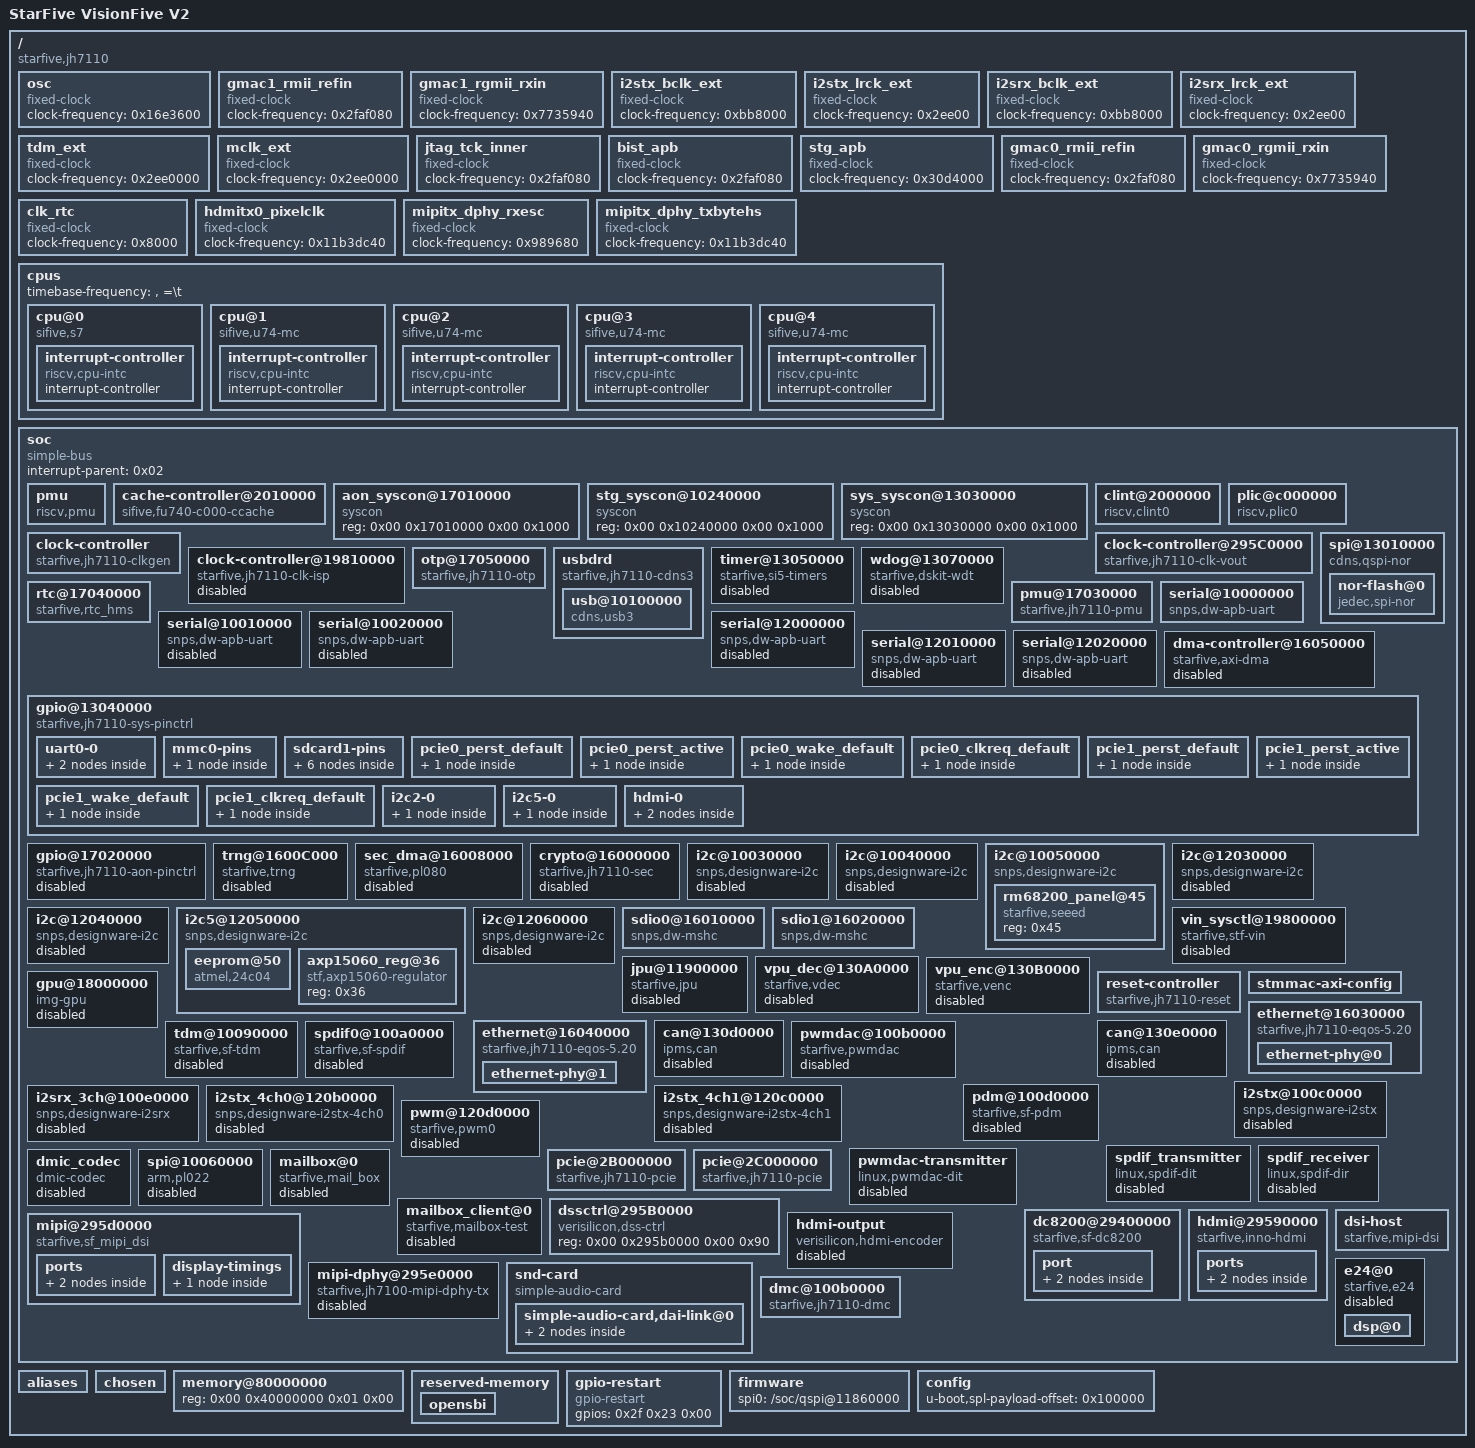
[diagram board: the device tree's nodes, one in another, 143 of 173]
/dts-v1/;

/ {
	serial-number = "VF7110B1-2253-D008E000-00005629";
	compatible = "starfive,jh7110";
	#address-cells = <0x02>;
	#size-cells = <0x02>;
	model = "StarFive VisionFive V2";

	osc {
		compatible = "fixed-clock";
		#clock-cells = <0x00>;
		clock-frequency = <0x16e3600>;
		u-boot,dm-spl;
		phandle = <0x08>;
	};

	gmac1_rmii_refin {
		compatible = "fixed-clock";
		#clock-cells = <0x00>;
		clock-frequency = <0x2faf080>;
		u-boot,dm-spl;
		phandle = <0x09>;
	};

	gmac1_rgmii_rxin {
		compatible = "fixed-clock";
		#clock-cells = <0x00>;
		clock-frequency = <0x7735940>;
		phandle = <0x30>;
	};

	i2stx_bclk_ext {
		compatible = "fixed-clock";
		#clock-cells = <0x00>;
		clock-frequency = <0xbb8000>;
		phandle = <0x31>;
	};

	i2stx_lrck_ext {
		compatible = "fixed-clock";
		#clock-cells = <0x00>;
		clock-frequency = <0x2ee00>;
		phandle = <0x32>;
	};

	i2srx_bclk_ext {
		compatible = "fixed-clock";
		#clock-cells = <0x00>;
		clock-frequency = <0xbb8000>;
		phandle = <0x33>;
	};

	i2srx_lrck_ext {
		compatible = "fixed-clock";
		#clock-cells = <0x00>;
		clock-frequency = <0x2ee00>;
		phandle = <0x34>;
	};

	tdm_ext {
		compatible = "fixed-clock";
		#clock-cells = <0x00>;
		clock-frequency = <0x2ee0000>;
		phandle = <0x35>;
	};

	mclk_ext {
		compatible = "fixed-clock";
		#clock-cells = <0x00>;
		clock-frequency = <0x2ee0000>;
		phandle = <0x36>;
	};

	jtag_tck_inner {
		compatible = "fixed-clock";
		#clock-cells = <0x00>;
		clock-frequency = <0x2faf080>;
		phandle = <0x37>;
	};

	bist_apb {
		compatible = "fixed-clock";
		#clock-cells = <0x00>;
		clock-frequency = <0x2faf080>;
		phandle = <0x38>;
	};

	stg_apb {
		compatible = "fixed-clock";
		#clock-cells = <0x00>;
		clock-frequency = <0x30d4000>;
		u-boot,dm-spl;
		phandle = <0x0a>;
	};

	gmac0_rmii_refin {
		compatible = "fixed-clock";
		#clock-cells = <0x00>;
		clock-frequency = <0x2faf080>;
		u-boot,dm-spl;
		phandle = <0x0b>;
	};

	gmac0_rgmii_rxin {
		compatible = "fixed-clock";
		#clock-cells = <0x00>;
		clock-frequency = <0x7735940>;
		phandle = <0x39>;
	};

	clk_rtc {
		compatible = "fixed-clock";
		#clock-cells = <0x00>;
		clock-frequency = <0x8000>;
		phandle = <0x3a>;
	};

	hdmitx0_pixelclk {
		compatible = "fixed-clock";
		#clock-cells = <0x00>;
		clock-frequency = <0x11b3dc40>;
		phandle = <0x0c>;
	};

	mipitx_dphy_rxesc {
		compatible = "fixed-clock";
		#clock-cells = <0x00>;
		clock-frequency = <0x989680>;
		phandle = <0x0d>;
	};

	mipitx_dphy_txbytehs {
		compatible = "fixed-clock";
		#clock-cells = <0x00>;
		clock-frequency = <0x11b3dc40>;
		phandle = <0x0e>;
	};

	cpus {
		#address-cells = <0x01>;
		#size-cells = <0x00>;
		u-boot,dm-spl;
		timebase-frequency = "", "=\t";
		phandle = <0x3b>;

		cpu@0 {
			compatible = "sifive,s7", "riscv";
			reg = <0x00>;
			d-cache-block-size = <0x40>;
			d-cache-sets = <0x40>;
			d-cache-size = <0x2000>;
			d-tlb-sets = <0x01>;
			d-tlb-size = <0x28>;
			device_type = "cpu";
			i-cache-block-size = <0x40>;
			i-cache-sets = <0x40>;
			i-cache-size = <0x4000>;
			i-tlb-sets = <0x01>;
			i-tlb-size = <0x28>;
			mmu-type = "riscv,sv39";
			next-level-cache = <0x01>;
			riscv,isa = "rv64imacu_zba_zbb";
			tlb-split;
			status = "okay";
			u-boot,dm-spl;
			phandle = <0x3c>;

			interrupt-controller {
				#interrupt-cells = <0x01>;
				compatible = "riscv,cpu-intc";
				interrupt-controller;
				u-boot,dm-spl;
				phandle = <0x03>;
			};
		};

		cpu@1 {
			compatible = "sifive,u74-mc", "riscv";
			reg = <0x01>;
			d-cache-block-size = <0x40>;
			d-cache-sets = <0x40>;
			d-cache-size = <0x8000>;
			d-tlb-sets = <0x01>;
			d-tlb-size = <0x28>;
			device_type = "cpu";
			i-cache-block-size = <0x40>;
			i-cache-sets = <0x40>;
			i-cache-size = <0x8000>;
			i-tlb-sets = <0x01>;
			i-tlb-size = <0x28>;
			mmu-type = "riscv,sv39";
			next-level-cache = <0x01>;
			riscv,isa = "rv64imafdcbsux_zba_zbb";
			tlb-split;
			status = "okay";
			u-boot,dm-spl;
			phandle = <0x3d>;

			interrupt-controller {
				#interrupt-cells = <0x01>;
				compatible = "riscv,cpu-intc";
				interrupt-controller;
				u-boot,dm-spl;
				phandle = <0x04>;
			};
		};

		cpu@2 {
			compatible = "sifive,u74-mc", "riscv";
			reg = <0x02>;
			d-cache-block-size = <0x40>;
			d-cache-sets = <0x40>;
			d-cache-size = <0x8000>;
			d-tlb-sets = <0x01>;
			d-tlb-size = <0x28>;
			device_type = "cpu";
			i-cache-block-size = <0x40>;
			i-cache-sets = <0x40>;
			i-cache-size = <0x8000>;
			i-tlb-sets = <0x01>;
			i-tlb-size = <0x28>;
			mmu-type = "riscv,sv39";
			next-level-cache = <0x01>;
			riscv,isa = "rv64imafdcbsux_zba_zbb";
			tlb-split;
			status = "okay";
			u-boot,dm-spl;
			phandle = <0x3e>;

			interrupt-controller {
				#interrupt-cells = <0x01>;
				compatible = "riscv,cpu-intc";
				interrupt-controller;
				u-boot,dm-spl;
				phandle = <0x05>;
			};
		};

		cpu@3 {
			compatible = "sifive,u74-mc", "riscv";
			reg = <0x03>;
			d-cache-block-size = <0x40>;
			d-cache-sets = <0x40>;
			d-cache-size = <0x8000>;
			d-tlb-sets = <0x01>;
			d-tlb-size = <0x28>;
			device_type = "cpu";
			i-cache-block-size = <0x40>;
			i-cache-sets = <0x40>;
			i-cache-size = <0x8000>;
			i-tlb-sets = <0x01>;
			i-tlb-size = <0x28>;
			mmu-type = "riscv,sv39";
			next-level-cache = <0x01>;
			riscv,isa = "rv64imafdcbsux_zba_zbb";
			tlb-split;
			status = "okay";
			u-boot,dm-spl;
			phandle = <0x3f>;

			interrupt-controller {
				#interrupt-cells = <0x01>;
				compatible = "riscv,cpu-intc";
				interrupt-controller;
				u-boot,dm-spl;
				phandle = <0x06>;
			};
		};

		cpu@4 {
			compatible = "sifive,u74-mc", "riscv";
			reg = <0x04>;
			d-cache-block-size = <0x40>;
			d-cache-sets = <0x40>;
			d-cache-size = <0x8000>;
			d-tlb-sets = <0x01>;
			d-tlb-size = <0x28>;
			device_type = "cpu";
			i-cache-block-size = <0x40>;
			i-cache-sets = <0x40>;
			i-cache-size = <0x8000>;
			i-tlb-sets = <0x01>;
			i-tlb-size = <0x28>;
			mmu-type = "riscv,sv39";
			next-level-cache = <0x01>;
			riscv,isa = "rv64imafdcbsux_zba_zbb";
			tlb-split;
			status = "okay";
			u-boot,dm-spl;
			phandle = <0x40>;

			interrupt-controller {
				#interrupt-cells = <0x01>;
				compatible = "riscv,cpu-intc";
				interrupt-controller;
				u-boot,dm-spl;
				phandle = <0x07>;
			};
		};
	};

	soc {
		compatible = "simple-bus";
		interrupt-parent = <0x02>;
		#address-cells = <0x02>;
		#size-cells = <0x02>;
		#clock-cells = <0x01>;
		ranges;
		u-boot,dm-spl;
		phandle = <0x41>;

		pmu {
			compatible = "riscv,pmu";
			riscv,event-to-mhpmcounters = <0x05 0x06 0x18>;
			riscv,event-to-mhpmevent = <0x05 0x00 0x4000 0x06 0x00 0x4001>;
			riscv,raw-event-to-mhpmcounters = <0x00 0x100 0xffffffff 0xffffffff 0x18 0x00 0x200 0xffffffff 0xffffffff 0x18 0x00 0x400 0xffffffff 0xffffffff 0x18 0x00 0x800 0xffffffff 0xffffffff 0x18 0x00 0x1000 0xffffffff 0xffffffff 0x18 0x00 0x2000 0xffffffff 0xffffffff 0x18 0x00 0x4000 0xffffffff 0xffffffff 0x18 0x00 0x8000 0xffffffff 0xffffffff 0x18 0x00 0x10000 0xffffffff 0xffffffff 0x18 0x00 0x20000 0xffffffff 0xffffffff 0x18 0x00 0x40000 0xffffffff 0xffffffff 0x18 0x00 0x80000 0xffffffff 0xffffffff 0x18 0x00 0x100000 0xffffffff 0xffffffff 0x18 0x00 0x200000 0xffffffff 0xffffffff 0x18 0x00 0x400000 0xffffffff 0xffffffff 0x18 0x00 0x800000 0xffffffff 0xffffffff 0x18 0x00 0x1000000 0xffffffff 0xffffffff 0x18 0x00 0x2000000 0xffffffff 0xffffffff 0x18 0x00 0x101 0xffffffff 0xffffffff 0x18 0x00 0x201 0xffffffff 0xffffffff 0x18 0x00 0x401 0xffffffff 0xffffffff 0x18 0x00 0x801 0xffffffff 0xffffffff 0x18 0x00 0x1001 0xffffffff 0xffffffff 0x18 0x00 0x2001 0xffffffff 0xffffffff 0x18 0x00 0x4001 0xffffffff 0xffffffff 0x18 0x00 0x8001 0xffffffff 0xffffffff 0x18 0x00 0x10001 0xffffffff 0xffffffff 0x18 0x00 0x20001 0xffffffff 0xffffffff 0x18 0x00 0x40001 0xffffffff 0xffffffff 0x18 0x00 0x102 0xffffffff 0xffffffff 0x18 0x00 0x202 0xffffffff 0xffffffff 0x18 0x00 0x402 0xffffffff 0xffffffff 0x18 0x00 0x802 0xffffffff 0xffffffff 0x18 0x00 0x1002 0xffffffff 0xffffffff 0x18 0x00 0x2002 0xffffffff 0xffffffff 0x18>;
		};

		cache-controller@2010000 {
			compatible = "sifive,fu740-c000-ccache", "cache";
			reg = <0x00 0x2010000 0x00 0x4000 0x00 0x2030000 0x00 0x80000 0x00 0x8000000 0x00 0x2000000>;
			reg-names = "control", "prefetcher", "sideband";
			interrupts = <0x01 0x03 0x04 0x02>;
			cache-block-size = <0x40>;
			cache-level = <0x02>;
			cache-sets = <0x800>;
			cache-size = <0x200000>;
			cache-unified;
			prefetch-dist-size = <0x04>;
			prefetch-hart-mask = <0x1e>;
			prefetch-enable;
			phandle = <0x01>;
		};

		aon_syscon@17010000 {
			compatible = "syscon";
			reg = <0x00 0x17010000 0x00 0x1000>;
			phandle = <0x42>;
		};

		stg_syscon@10240000 {
			compatible = "syscon";
			reg = <0x00 0x10240000 0x00 0x1000>;
			phandle = <0x11>;
		};

		sys_syscon@13030000 {
			compatible = "syscon";
			reg = <0x00 0x13030000 0x00 0x1000>;
			phandle = <0x12>;
		};

		clint@2000000 {
			compatible = "riscv,clint0";
			reg = <0x00 0x2000000 0x00 0x10000>;
			reg-names = "control";
			interrupts-extended = <0x03 0x03 0x03 0x07 0x04 0x03 0x04 0x07 0x05 0x03 0x05 0x07 0x06 0x03 0x06 0x07 0x07 0x03 0x07 0x07>;
			#interrupt-cells = <0x01>;
			u-boot,dm-spl;
			phandle = <0x43>;
		};

		plic@c000000 {
			compatible = "riscv,plic0";
			reg = <0x00 0xc000000 0x00 0x4000000>;
			reg-names = "control";
			interrupts-extended = <0x03 0x0b 0x04 0x0b 0x04 0x09 0x05 0x0b 0x05 0x09 0x06 0x0b 0x06 0x09 0x07 0x0b 0x07 0x09>;
			interrupt-controller;
			#interrupt-cells = <0x01>;
			riscv,max-priority = <0x07>;
			riscv,ndev = <0x88>;
			phandle = <0x02>;
		};

		clock-controller {
			compatible = "starfive,jh7110-clkgen";
			reg = <0x00 0x13020000 0x00 0x10000 0x00 0x10230000 0x00 0x10000 0x00 0x17000000 0x00 0x10000>;
			reg-names = "sys", "stg", "aon";
			clocks = <0x08 0x09 0x0a 0x0b>;
			clock-names = "osc", "gmac1_rmii_refin", "stg_apb", "gmac0_rmii_refin";
			#clock-cells = <0x01>;
			status = "okay";
			u-boot,dm-spl;
			phandle = <0x0f>;
		};

		clock-controller@295C0000 {
			compatible = "starfive,jh7110-clk-vout";
			reg = <0x00 0x295c0000 0x00 0x10000>;
			reg-names = "vout";
			clocks = <0x0c 0x0d 0x0e>;
			clock-names = "hdmitx0_pixelclk", "mipitx_dphy_rxesc", "mipitx_dphy_txbytehs";
			#clock-cells = <0x01>;
			status = "okay";
			phandle = <0x24>;
		};

		clock-controller@19810000 {
			compatible = "starfive,jh7110-clk-isp";
			reg = <0x00 0x19810000 0x00 0x10000>;
			reg-names = "isp";
			#clock-cells = <0x01>;
			clocks = <0x0f 0x10a 0x0f 0x33 0x0f 0x34>;
			clock-names = "u0_dom_isp_top_clk_dom_isp_top_clk_dvp", "u0_dom_isp_top_clk_dom_isp_top_clk_ispcore_2x", "u0_dom_isp_top_clk_dom_isp_top_clk_isp_axi";
			resets = <0x10 0x29 0x10 0x2a>;
			reset-names = "rst_isp_top_n", "rst_isp_top_axi";
			status = "disabled";
			phandle = <0x18>;
		};

		spi@13010000 {
			compatible = "cdns,qspi-nor";
			#address-cells = <0x01>;
			#size-cells = <0x00>;
			reg = <0x00 0x13010000 0x00 0x10000 0x00 0x21000000 0x00 0x400000>;
			clocks = <0x0f 0x5a>;
			clock-names = "clk_ref";
			resets = <0x10 0x3e 0x10 0x3d 0x10 0x3f>;
			resets-names = "rst_apb", "rst_ahb", "rst_ref";
			cdns,fifo-depth = <0x100>;
			cdns,fifo-width = <0x04>;
			spi-max-frequency = <0xee6b280>;
			status = "okay";
			u-boot,dm-spl;
			phandle = <0x44>;

			nor-flash@0 {
				compatible = "jedec,spi-nor";
				reg = <0x00>;
				spi-max-frequency = <0x5f5e100>;
				cdns,tshsl-ns = <0x01>;
				cdns,tsd2d-ns = <0x01>;
				cdns,tchsh-ns = <0x01>;
				cdns,tslch-ns = <0x01>;
				u-boot,dm-spl;
				phandle = <0x45>;
			};
		};

		otp@17050000 {
			compatible = "starfive,jh7110-otp";
			reg = <0x00 0x17050000 0x00 0x10000>;
			clock-frequency = "", "=\t";
			clocks = <0x0f 0xe4>;
			clock-names = "apb";
			phandle = <0x46>;
		};

		usbdrd {
			compatible = "starfive,jh7110-cdns3";
			dma-coherent;
			#address-cells = <0x02>;
			#size-cells = <0x02>;
			reg = <0x00 0x10210000 0x00 0x1000 0x00 0x10200000 0x00 0x1000>;
			clocks = <0x0f 0x5f 0x0f 0xc4 0x0f 0xc2 0x0f 0xc3 0x0f 0xbf 0x0f 0xc1 0x0f 0xc0>;
			clock-names = "125m", "app", "lpm", "stb", "apb", "axi", "utmi";
			resets = <0x10 0x8a 0x10 0x88 0x10 0x87 0x10 0x89>;
			reset-names = "pwrup", "apb", "axi", "utmi";
			starfive,stg-syscon = <0x11 0x04 0xc4 0x148 0x1f4>;
			starfive,sys-syscon = <0x12 0x18>;
			status = "okay";
			starfive,usb2-only = <0x01>;
			phandle = <0x47>;

			usb@10100000 {
				compatible = "cdns,usb3";
				reg = <0x00 0x10100000 0x00 0x10000 0x00 0x10110000 0x00 0x10000 0x00 0x10120000 0x00 0x10000>;
				reg-names = "otg", "xhci", "dev";
				interrupts = <0x64 0x6c 0x6e>;
				interrupt-names = "host", "peripheral", "otg";
				phy-names = "cdns3,usb3-phy", "cnds3,usb2-phy";
				maximum-speed = "super-speed";
				dr_mode = "peripheral";
				phandle = <0x48>;
			};
		};

		timer@13050000 {
			compatible = "starfive,si5-timers";
			reg = <0x00 0x13050000 0x00 0x10000>;
			interrupts = <0x45 0x46 0x47 0x48>;
			interrupt-names = "timer0", "timer1", "timer2", "timer3";
			clocks = <0x0f 0x7d 0x0f 0x7e 0x0f 0x7f 0x0f 0x80 0x0f 0x7c>;
			clock-names = "timer0", "timer1", "timer2", "timer3", "apb_clk";
			clock-frequency = <0x1e8480>;
			status = "disabled";
			phandle = <0x49>;
		};

		wdog@13070000 {
			compatible = "starfive,dskit-wdt";
			reg = <0x00 0x13070000 0x00 0x10000>;
			interrupts = <0x44>;
			interrupt-names = "wdog";
			clock-frequency = <0x1e8480>;
			clocks = <0x0f 0x7b 0x0f 0x7a>;
			clock-names = "core_clk", "apb_clk";
			resets = <0x10 0x6d 0x10 0x6e>;
			reset-names = "rst_apb", "rst_core";
			timeout-sec = <0x0f>;
			status = "disabled";
			phandle = <0x4a>;
		};

		rtc@17040000 {
			compatible = "starfive,rtc_hms";
			reg = <0x00 0x17040000 0x00 0x10000>;
			interrupts = <0x0a 0x0b 0x0c>;
			interrupt-names = "rtc_ms_pulse", "rtc_sec_pulse", "rtc";
			clocks = <0x0f 0xe5 0x0f 0xe8>;
			clock-names = "pclk", "cal_clk";
			resets = <0x10 0xa5 0x10 0xa6 0x10 0xa7>;
			reset-names = "rst_apb", "rst_cal", "rst_osc";
			rtc,cal-clock-freq = <0xf4240>;
			status = "okay";
			phandle = <0x4b>;
		};

		pmu@17030000 {
			compatible = "starfive,jh7110-pmu";
			reg = <0x00 0x17030000 0x00 0x10000>;
			interrupts = <0x6f>;
			status = "okay";
			phandle = <0x4c>;
		};

		serial@10000000 {
			compatible = "snps,dw-apb-uart";
			reg = <0x00 0x10000000 0x00 0x10000>;
			reg-io-width = <0x04>;
			reg-shift = <0x02>;
			clocks = <0x0f 0x92 0x0f 0x91>;
			clock-names = "baudclk", "apb_pclk";
			resets = <0x10 0x53 0x10 0x54>;
			interrupts = <0x20>;
			status = "okay";
			reg-offset = <0x00>;
			current-speed = <0x1c200>;
			pinctrl-names = "default";
			pinctrl-0 = <0x13>;
			clock-frequency = <0x16e3600>;
			u-boot,dm-spl;
			phandle = <0x4d>;
		};

		serial@10010000 {
			compatible = "snps,dw-apb-uart";
			reg = <0x00 0x10010000 0x00 0x10000>;
			reg-io-width = <0x04>;
			reg-shift = <0x02>;
			clocks = <0x0f 0x94 0x0f 0x93>;
			clock-names = "baudclk", "apb_pclk";
			resets = <0x10 0x55 0x10 0x56>;
			interrupts = <0x21>;
			status = "disabled";
			phandle = <0x4e>;
		};

		serial@10020000 {
			compatible = "snps,dw-apb-uart";
			reg = <0x00 0x10020000 0x00 0x10000>;
			reg-io-width = <0x04>;
			reg-shift = <0x02>;
			clocks = <0x0f 0x96 0x0f 0x95>;
			clock-names = "baudclk", "apb_pclk";
			resets = <0x10 0x57 0x10 0x58>;
			interrupts = <0x22>;
			status = "disabled";
			phandle = <0x4f>;
		};

		serial@12000000 {
			compatible = "snps,dw-apb-uart";
			reg = <0x00 0x12000000 0x00 0x10000>;
			reg-io-width = <0x04>;
			reg-shift = <0x02>;
			clocks = <0x0f 0x98 0x0f 0x97>;
			clock-names = "baudclk", "apb_pclk";
			resets = <0x10 0x59 0x10 0x5a>;
			interrupts = <0x2d>;
			status = "disabled";
			phandle = <0x50>;
		};

		serial@12010000 {
			compatible = "snps,dw-apb-uart";
			reg = <0x00 0x12010000 0x00 0x10000>;
			reg-io-width = <0x04>;
			reg-shift = <0x02>;
			clocks = <0x0f 0x9a 0x0f 0x99>;
			clock-names = "baudclk", "apb_pclk";
			resets = <0x10 0x5b 0x10 0x5c>;
			interrupts = <0x2e>;
			status = "disabled";
			phandle = <0x51>;
		};

		serial@12020000 {
			compatible = "snps,dw-apb-uart";
			reg = <0x00 0x12020000 0x00 0x10000>;
			reg-io-width = <0x04>;
			reg-shift = <0x02>;
			clocks = <0x0f 0x9c 0x0f 0x9b>;
			clock-names = "baudclk", "apb_pclk";
			resets = <0x10 0x5d 0x10 0x5e>;
			interrupts = <0x2f>;
			status = "disabled";
			phandle = <0x52>;
		};

		dma-controller@16050000 {
			compatible = "starfive,axi-dma";
			reg = <0x00 0x16050000 0x00 0x10000>;
			clocks = <0x0f 0xd9 0x0f 0xda>;
			clock-names = "core-clk", "cfgr-clk";
			resets = <0x10 0x85 0x10 0x86>;
			reset-names = "rst_axi", "rst_ahb";
			interrupts = <0x49>;
			#dma-cells = <0x02>;
			dma-channels = <0x04>;
			snps,dma-masters = <0x01>;
			snps,data-width = <0x03>;
			snps,num-hs-if = <0x38>;
			snps,block-size = <0x10000 0x10000 0x10000 0x10000>;
			snps,priority = <0x00 0x01 0x02 0x03>;
			snps,axi-max-burst-len = <0x10>;
			status = "disabled";
			phandle = <0x1a>;
		};

		gpio@13040000 {
			compatible = "starfive,jh7110-sys-pinctrl";
			reg = <0x00 0x13040000 0x00 0x10000>;
			reg-names = "control";
			interrupts = <0x5b>;
			interrupt-controller;
			gpio-controller;
			#gpio-cells = <0x02>;
			ngpios = <0x40>;
			status = "okay";
			u-boot,dm-spl;
			phandle = <0x2f>;

			uart0-0 {
				phandle = <0x13>;

				tx-pins {
					pinmux = <0xff140005>;
					bias-disable;
					drive-strength = <0x0c>;
					input-disable;
					input-schmitt-disable;
					slew-rate = <0x00>;
				};

				rx-pins {
					pinmux = <0xe000406>;
					bias-pull-up;
					drive-strength = <0x02>;
					input-enable;
					input-schmitt-enable;
					slew-rate = <0x00>;
				};
			};

			mmc0-pins {
				phandle = <0x16>;

				mmc0-pins-rest {
					pinmux = <0xff13003e>;
					bias-pull-up;
					drive-strength = <0x0c>;
					input-disable;
					input-schmitt-disable;
					slew-rate = <0x00>;
				};
			};

			sdcard1-pins {
				phandle = <0x17>;

				sdcard1-pins0 {
					pinmux = <0xff37000a>;
					bias-pull-up;
					drive-strength = <0x0c>;
					input-disable;
					input-schmitt-disable;
					slew-rate = <0x00>;
				};

				sdcard1-pins1 {
					pinmux = <0x2c394c09>;
					bias-pull-up;
					drive-strength = <0x0c>;
					input-enable;
					input-schmitt-enable;
					slew-rate = <0x00>;
				};

				sdcard1-pins2 {
					pinmux = <0x2d3a500b>;
					bias-pull-up;
					drive-strength = <0x0c>;
					input-enable;
					input-schmitt-enable;
					slew-rate = <0x00>;
				};

				sdcard1-pins3 {
					pinmux = <0x2e3b540c>;
					bias-pull-up;
					drive-strength = <0x0c>;
					input-enable;
					input-schmitt-enable;
					slew-rate = <0x00>;
				};

				sdcard1-pins4 {
					pinmux = <0x2f3c5807>;
					bias-pull-up;
					drive-strength = <0x0c>;
					input-enable;
					input-schmitt-enable;
					slew-rate = <0x00>;
				};

				sdcard1-pins5 {
					pinmux = <0x303d5c08>;
					bias-pull-up;
					drive-strength = <0x0c>;
					input-enable;
					input-schmitt-enable;
					slew-rate = <0x00>;
				};
			};

			pcie0_perst_default {
				phandle = <0x1b>;

				perst-pins {
					pinmux = <0xff01001a>;
					drive-strength = <0x02>;
					input-disable;
					input-schmitt-disable;
					slew-rate = <0x00>;
				};
			};

			pcie0_perst_active {
				phandle = <0x1c>;

				perst-pins {
					pinmux = <0xff00001a>;
					drive-strength = <0x02>;
					input-disable;
					input-schmitt-disable;
					slew-rate = <0x00>;
				};
			};

			pcie0_wake_default {
				phandle = <0x1d>;

				wake-pins {
					pinmux = <0xff010020>;
					drive-strength = <0x02>;
					input-enable;
					input-schmitt-disable;
					slew-rate = <0x00>;
				};
			};

			pcie0_clkreq_default {
				phandle = <0x1e>;

				clkreq-pins {
					pinmux = <0xff01001b>;
					drive-strength = <0x02>;
					input-enable;
					input-schmitt-disable;
					slew-rate = <0x00>;
				};
			};

			pcie1_perst_default {
				phandle = <0x1f>;

				perst-pins {
					pinmux = <0xff01001c>;
					drive-strength = <0x02>;
					input-disable;
					input-schmitt-disable;
					slew-rate = <0x00>;
				};
			};

			pcie1_perst_active {
				phandle = <0x20>;

				perst-pins {
					pinmux = <0xff00001c>;
					drive-strength = <0x02>;
					input-disable;
					input-schmitt-disable;
					slew-rate = <0x00>;
				};
			};

			pcie1_wake_default {
				phandle = <0x21>;

				wake-pins {
					pinmux = <0xff010015>;
					drive-strength = <0x02>;
					input-enable;
					input-schmitt-disable;
					slew-rate = <0x00>;
				};
			};

			pcie1_clkreq_default {
				phandle = <0x22>;

				clkreq-pins {
					pinmux = <0xff01001d>;
					drive-strength = <0x02>;
					input-enable;
					input-schmitt-disable;
					slew-rate = <0x00>;
				};
			};

			i2c2-0 {
				phandle = <0x15>;

				i2c-pins {
					pinmux = <0x3b007803 0x3c007c02>;
					bias-disable;
					input-enable;
					input-schmitt-enable;
				};
			};

			i2c5-0 {
				phandle = <0x53>;

				i2c-pins {
					pinmux = <0x4f00a813 0x5000ac14>;
					bias-disable;
					input-enable;
					input-schmitt-enable;
				};
			};

			hdmi-0 {
				phandle = <0x27>;

				cec-pins {
					pinmux = <0x50a080e>;
					bias-pull-up;
					input-enable;
				};

				hpd-pins {
					pinmux = <0x800040f>;
					input-enable;
				};
			};
		};

		gpio@17020000 {
			compatible = "starfive,jh7110-aon-pinctrl";
			reg = <0x00 0x17020000 0x00 0x10000>;
			reg-names = "control";
			interrupts = <0x5a>;
			interrupt-controller;
			gpio-controller;
			#gpio-cells = <0x02>;
			ngpios = <0x04>;
			status = "disabled";
			u-boot,dm-spl;
			phandle = <0x54>;
		};

		trng@1600C000 {
			compatible = "starfive,trng";
			reg = <0x00 0x1600c000 0x00 0x4000>;
			clocks = <0x0f 0xcd 0x0f 0xce>;
			clock-names = "hclk", "miscahb_clk";
			resets = <0x10 0x83>;
			interrupts = <0x1e>;
			status = "disabled";
			phandle = <0x55>;
		};

		sec_dma@16008000 {
			compatible = "starfive,pl080";
			reg = <0x00 0x16008000 0x00 0x4000>;
			reg-names = "sec_dma";
			interrupts = <0x1d>;
			clocks = <0x0f 0xcd 0x0f 0xce>;
			clock-names = "sec_hclk", "sec_ahb";
			resets = <0x10 0x83>;
			reset-names = "sec_hre";
			lli-bus-interface-ahb1;
			mem-bus-interface-ahb1;
			memcpy-burst-size = <0x100>;
			memcpy-bus-width = <0x20>;
			#dma-cells = <0x02>;
			status = "disabled";
			phandle = <0x14>;
		};

		crypto@16000000 {
			compatible = "starfive,jh7110-sec";
			reg = <0x00 0x16000000 0x00 0x4000 0x00 0x16008000 0x00 0x4000>;
			reg-names = "secreg", "secdma";
			interrupts = <0x1c 0x1d>;
			interrupt-names = "secirq", "dmairq";
			clocks = <0x0f 0xcd 0x0f 0xce>;
			clock-names = "sec_hclk", "sec_ahb";
			resets = <0x10 0x83>;
			reset-names = "sec_hre";
			enable-dma = "true";
			dmas = <0x14 0x01 0x02 0x14 0x00 0x02>;
			dma-names = "sec_m", "sec_p";
			status = "disabled";
			phandle = <0x56>;
		};

		i2c@10030000 {
			compatible = "snps,designware-i2c";
			reg = <0x00 0x10030000 0x00 0x10000>;
			clocks = <0x0f 0x8a>;
			clock-names = "pclk";
			resets = <0x10 0x4c>;
			interrupts = <0x23>;
			#address-cells = <0x01>;
			#size-cells = <0x00>;
			status = "disabled";
			phandle = <0x57>;
		};

		i2c@10040000 {
			compatible = "snps,designware-i2c";
			reg = <0x00 0x10040000 0x00 0x10000>;
			clocks = <0x0f 0x8b>;
			clock-names = "pclk";
			resets = <0x10 0x4d>;
			interrupts = <0x24>;
			#address-cells = <0x01>;
			#size-cells = <0x00>;
			status = "disabled";
			phandle = <0x58>;
		};

		i2c@10050000 {
			compatible = "snps,designware-i2c";
			reg = <0x00 0x10050000 0x00 0x10000>;
			clocks = <0x0f 0x8c>;
			clock-names = "pclk";
			resets = <0x10 0x4e>;
			interrupts = <0x25>;
			#address-cells = <0x01>;
			#size-cells = <0x00>;
			status = "okay";
			clock-frequency = <0x186a0>;
			i2c-sda-hold-time-ns = <0x12c>;
			i2c-sda-falling-time-ns = <0xbb8>;
			i2c-scl-falling-time-ns = <0xbb8>;
			auto_calc_scl_lhcnt;
			pinctrl-names = "default";
			pinctrl-0 = <0x15>;
			phandle = <0x59>;

			rm68200_panel@45 {
				compatible = "starfive,seeed";
				reg = <0x45>;
				phandle = <0x29>;
			};
		};

		i2c@12030000 {
			compatible = "snps,designware-i2c";
			reg = <0x00 0x12030000 0x00 0x10000>;
			clocks = <0x0f 0x8d>;
			clock-names = "pclk";
			resets = <0x10 0x4f>;
			interrupts = <0x30>;
			#address-cells = <0x01>;
			#size-cells = <0x00>;
			status = "disabled";
			phandle = <0x5a>;
		};

		i2c@12040000 {
			compatible = "snps,designware-i2c";
			reg = <0x00 0x12040000 0x00 0x10000>;
			clocks = <0x0f 0x8e>;
			clock-names = "pclk";
			resets = <0x10 0x50>;
			interrupts = <0x31>;
			#address-cells = <0x01>;
			#size-cells = <0x00>;
			status = "disabled";
			phandle = <0x5b>;
		};

		i2c5@12050000 {
			compatible = "snps,designware-i2c";
			reg = <0x00 0x12050000 0x00 0x10000>;
			clocks = <0x0f 0x8f>;
			clock-names = "pclk";
			resets = <0x10 0x51>;
			interrupts = <0x32>;
			#address-cells = <0x01>;
			#size-cells = <0x00>;
			status = "okay";
			clock-frequency = <0x186a0>;
			i2c-sda-hold-time-ns = <0x12c>;
			i2c-sda-falling-time-ns = <0xbb8>;
			i2c-scl-falling-time-ns = <0xbb8>;
			auto_calc_scl_lhcnt;
			u-boot,dm-spl;
			phandle = <0x5c>;

			eeprom@50 {
				compatible = "atmel,24c04";
				reg = <0x50>;
				pagesize = <0x10>;
				u-boot,dm-spl;
			};

			axp15060_reg@36 {
				compatible = "stf,axp15060-regulator";
				reg = <0x36>;
				phandle = <0x5d>;
			};
		};

		i2c@12060000 {
			compatible = "snps,designware-i2c";
			reg = <0x00 0x12060000 0x00 0x10000>;
			clocks = <0x0f 0x90>;
			clock-names = "pclk";
			resets = <0x10 0x52>;
			interrupts = <0x33>;
			#address-cells = <0x01>;
			#size-cells = <0x00>;
			status = "disabled";
			phandle = <0x5e>;
		};

		sdio0@16010000 {
			compatible = "snps,dw-mshc";
			reg = <0x00 0x16010000 0x00 0x10000>;
			clocks = <0x0f 0x5b 0x0f 0x5d>;
			clock-names = "biu", "ciu";
			resets = <0x10 0x40>;
			reset-names = "reset";
			assigned-clocks = <0x0f 0x5d>;
			assigned-clock-rates = <0x2faf080>;
			fifo-depth = <0x20>;
			bus-width = <0x08>;
			pinctrl-names = "default";
			pinctrl-0 = <0x16>;
			status = "okay";
			u-boot,dm-spl;
			phandle = <0x5f>;
		};

		sdio1@16020000 {
			compatible = "snps,dw-mshc";
			reg = <0x00 0x16020000 0x00 0x10000>;
			clocks = <0x0f 0x5c 0x0f 0x5e>;
			clock-names = "biu", "ciu";
			resets = <0x10 0x41>;
			reset-names = "reset";
			assigned-clocks = <0x0f 0x5e>;
			assigned-clock-rates = <0x2faf080>;
			fifo-depth = <0x20>;
			bus-width = <0x04>;
			pinctrl-names = "default";
			pinctrl-0 = <0x17>;
			status = "okay";
			u-boot,dm-spl;
			phandle = <0x60>;
		};

		vin_sysctl@19800000 {
			compatible = "starfive,stf-vin";
			reg = <0x00 0x19800000 0x00 0x10000 0x00 0x19810000 0x00 0x10000 0x00 0x19820000 0x00 0x10000 0x00 0x19830000 0x00 0x10000 0x00 0x19840000 0x00 0x10000 0x00 0x19870000 0x00 0x30000 0x00 0x198a0000 0x00 0x30000 0x00 0x11840000 0x00 0x10000 0x00 0x17030000 0x00 0x10000 0x00 0x13020000 0x00 0x10000>;
			reg-names = "mipi0", "vclk", "vrst", "mipi1", "sctrl", "isp0", "isp1", "trst", "pmu", "syscrg";
			clocks = <0x18 0x00 0x18 0x06 0x18 0x07 0x18 0x0d 0x18 0x02 0x18 0x0c 0x18 0x01 0x18 0x08 0x18 0x09 0x18 0x0a 0x18 0x0b>;
			clock-names = "clk_apb_func", "clk_pclk", "clk_sys_clk", "clk_wrapper_clk_c", "clk_dvp_inv", "clk_axiwr", "clk_mipi_rx0_pxl", "clk_pixel_clk_if0", "clk_pixel_clk_if1", "clk_pixel_clk_if2", "clk_pixel_clk_if3";
			resets = <0x10 0xc0 0x10 0xc1 0x10 0xc4 0x10 0xc9 0x10 0xca 0x10 0xcb 0x10 0xc5 0x10 0xc6 0x10 0xc7 0x10 0xc8 0x10 0xc2 0x10 0xc3>;
			reset-names = "rst_wrapper_p", "rst_wrapper_c", "rst_pclk", "rst_sys_clk", "rst_axird", "rst_axiwr", "rst_pixel_clk_if0", "rst_pixel_clk_if1", "rst_pixel_clk_if2", "rst_pixel_clk_if3", "rst_m31dphy_hw", "rst_m31dphy_b09_always_on";
			interrupts = <0x5c 0x57 0x56>;
			status = "disabled";
			phandle = <0x61>;
		};

		jpu@11900000 {
			compatible = "starfive,jpu";
			reg = <0x00 0x13090000 0x00 0x300>;
			interrupts = <0x0e>;
			clocks = <0x0f 0x42 0x0f 0x43 0x0f 0x44>;
			clock-names = "axi_clk", "core_clk", "apb_clk";
			resets = <0x10 0x2c 0x10 0x2d 0x10 0x2e>;
			reset-names = "rst_axi", "rst_core", "rst_apb";
			status = "disabled";
			phandle = <0x62>;
		};

		vpu_dec@130A0000 {
			compatible = "starfive,vdec";
			reg = <0x00 0x130a0000 0x00 0x10000>;
			interrupts = <0x0d>;
			clocks = <0x0f 0x46 0x0f 0x47 0x0f 0x48 0x0f 0x49 0x0f 0x4c>;
			clock-names = "axi_clk", "bpu_clk", "vce_clk", "apb_clk", "noc_bus";
			resets = <0x10 0x2f 0x10 0x30 0x10 0x31 0x10 0x32 0x10 0x35>;
			reset-names = "rst_axi", "rst_bpu", "rst_vce", "rst_apb", "rst_sram";
			starfive,vdec_noc_ctrl;
			status = "disabled";
			phandle = <0x63>;
		};

		vpu_enc@130B0000 {
			compatible = "starfive,venc";
			reg = <0x00 0x130b0000 0x00 0x10000>;
			interrupts = <0x0f>;
			clocks = <0x0f 0x4e 0x0f 0x4f 0x0f 0x50 0x0f 0x51 0x0f 0x52>;
			clock-names = "axi_clk", "bpu_clk", "vce_clk", "apb_clk", "noc_bus";
			resets = <0x10 0x36 0x10 0x37 0x10 0x38 0x10 0x39 0x10 0x3a>;
			reset-names = "rst_axi", "rst_bpu", "rst_vce", "rst_apb", "rst_sram";
			starfive,venc_noc_ctrl;
			status = "disabled";
			phandle = <0x64>;
		};

		reset-controller {
			compatible = "starfive,jh7110-reset";
			reg = <0x00 0x13020000 0x00 0x10000 0x00 0x10230000 0x00 0x10000 0x00 0x17000000 0x00 0x10000 0x00 0x19810000 0x00 0x10000 0x00 0x295c0000 0x00 0x10000>;
			reg-names = "syscrg", "stgcrg", "aoncrg", "ispcrg", "voutcrg";
			#reset-cells = <0x01>;
			status = "okay";
			u-boot,dm-spl;
			phandle = <0x10>;
		};

		stmmac-axi-config {
			snps,wr_osr_lmt = <0x0f>;
			snps,rd_osr_lmt = <0x0f>;
			snps,blen = <0x100 0x80 0x40 0x20 0x00 0x00 0x00>;
			phandle = <0x19>;
		};

		ethernet@16030000 {
			local-mac-address = [6c cf 39 00 5e f6];
			compatible = "starfive,jh7110-eqos-5.20";
			reg = <0x00 0x16030000 0x00 0x10000>;
			clock-names = "gtx", "tx", "ptp_ref", "stmmaceth", "pclk", "gtxc", "rmii_rtx";
			clocks = <0x0f 0x6c 0x0f 0xe0 0x0f 0x6d 0x0f 0xdd 0x0f 0xde 0x0f 0x6f 0x0f 0xdf>;
			resets = <0x10 0xa1 0x10 0xa0>;
			reset-names = "ahb", "stmmaceth";
			interrupts = <0x07 0x06 0x05>;
			interrupt-names = "macirq", "eth_wake_irq", "eth_lpi";
			max-frame-size = <0x2328>;
			phy-mode = "rgmii-id";
			snps,multicast-filter-bins = <0x100>;
			snps,perfect-filter-entries = <0x80>;
			rx-fifo-depth = <0x40000>;
			tx-fifo-depth = <0x20000>;
			snps,fixed-burst;
			snps,no-pbl-x8;
			snps,force_thresh_dma_mode;
			snps,axi-config = <0x19>;
			snps,tso;
			snps,en-tx-lpi-clockgating;
			snps,en-lpi;
			snps,write-requests = <0x02>;
			snps,read-requests = <0x10>;
			snps,burst-map = <0x07>;
			snps,txpbl = <0x10>;
			snps,rxpbl = <0x10>;
			status = "okay";
			#address-cells = <0x01>;
			#size-cells = <0x00>;
			phandle = <0x65>;

			ethernet-phy@0 {
				rgmii_sw_dr_2 = <0x00>;
				rgmii_sw_dr = <0x03>;
				rgmii_sw_dr_rxc = <0x06>;
				rxc_dly_en = <0x00>;
				rx_delay_sel = <0x0a>;
				tx_delay_sel_fe = <0x05>;
				tx_delay_sel = <0x0a>;
				tx_inverted_10 = <0x01>;
				tx_inverted_100 = <0x01>;
				tx_inverted_1000 = <0x01>;
				phandle = <0x66>;
			};
		};

		ethernet@16040000 {
			local-mac-address = [6c cf 39 00 5e f9];
			compatible = "starfive,jh7110-eqos-5.20";
			reg = <0x00 0x16040000 0x00 0x10000>;
			clock-names = "gtx", "tx", "ptp_ref", "stmmaceth", "pclk", "gtxc", "rmii_rtx";
			clocks = <0x0f 0x64 0x0f 0x69 0x0f 0x66 0x0f 0x61 0x0f 0x62 0x0f 0x6b 0x0f 0x65>;
			resets = <0x10 0x43 0x10 0x42>;
			reset-names = "ahb", "stmmaceth";
			interrupts = <0x4e 0x4d 0x4c>;
			interrupt-names = "macirq", "eth_wake_irq", "eth_lpi";
			max-frame-size = <0x2328>;
			phy-mode = "rgmii-id";
			snps,multicast-filter-bins = <0x100>;
			snps,perfect-filter-entries = <0x80>;
			rx-fifo-depth = <0x40000>;
			tx-fifo-depth = <0x20000>;
			snps,fixed-burst;
			snps,no-pbl-x8;
			snps,force_thresh_dma_mode;
			snps,axi-config = <0x19>;
			snps,tso;
			snps,en-tx-lpi-clockgating;
			snps,en-lpi;
			snps,write-requests = <0x02>;
			snps,read-requests = <0x10>;
			snps,burst-map = <0x07>;
			snps,txpbl = <0x10>;
			snps,rxpbl = <0x10>;
			status = "okay";
			#address-cells = <0x01>;
			#size-cells = <0x00>;
			phandle = <0x67>;

			ethernet-phy@1 {
				rgmii_sw_dr_2 = <0x00>;
				rgmii_sw_dr = <0x03>;
				rgmii_sw_dr_rxc = <0x06>;
				tx_delay_sel_fe = <0x05>;
				tx_delay_sel = <0x00>;
				rxc_dly_en = <0x00>;
				rx_delay_sel = <0x02>;
				tx_inverted_10 = <0x01>;
				tx_inverted_100 = <0x01>;
				tx_inverted_1000 = <0x00>;
				phandle = <0x68>;
			};
		};

		gpu@18000000 {
			compatible = "img-gpu";
			reg = <0x00 0x18000000 0x00 0x100000 0x00 0x130c000 0x00 0x10000>;
			clocks = <0x0f 0x30 0x0f 0x31 0x0f 0x2e 0x0f 0x2f 0x0f 0x32>;
			clock-names = "clk_apb", "clk_rtc", "clk_core", "clk_sys", "clk_axi";
			resets = <0x10 0x15 0x10 0x16>;
			reset-names = "rst_apb", "rst_doma";
			interrupts = <0x52>;
			current-clock = <0x7a1200>;
			status = "disabled";
			phandle = <0x69>;
		};

		can@130d0000 {
			compatible = "ipms,can";
			reg = <0x00 0x130d0000 0x00 0x1000>;
			interrupts = <0x70>;
			clocks = <0x0f 0x73 0x0f 0x75 0x0f 0x74>;
			clock-names = "apb_clk", "core_clk", "timer_clk";
			resets = <0x10 0x6f 0x10 0x70 0x10 0x71>;
			reset-names = "rst_apb", "rst_core", "rst_timer";
			starfive,sys-syscon = <0x12 0x10 0x03 0x08>;
			syscon,can_or_canfd = <0x00>;
			status = "disabled";
			phandle = <0x6a>;
		};

		can@130e0000 {
			compatible = "ipms,can";
			reg = <0x00 0x130e0000 0x00 0x1000>;
			interrupts = <0x71>;
			clocks = <0x0f 0x76 0x0f 0x78 0x0f 0x77>;
			clock-names = "apb_clk", "core_clk", "timer_clk";
			resets = <0x10 0x72 0x10 0x73 0x10 0x74>;
			reset-names = "rst_apb", "rst_core", "rst_timer";
			starfive,sys-syscon = <0x12 0x88 0x12 0x40000>;
			syscon,can_or_canfd = <0x00>;
			status = "disabled";
			phandle = <0x6b>;
		};

		tdm@10090000 {
			compatible = "starfive,sf-tdm";
			reg = <0x00 0x10090000 0x00 0x1000>;
			reg-names = "tdm";
			clocks = <0x0f 0x09 0x0f 0xb8 0x0f 0x0c 0x0f 0xb9 0x0f 0xba>;
			clock-names = "clk_ahb0", "clk_tdm_ahb", "clk_apb0", "clk_tdm_apb", "clk_tdm_intl";
			resets = <0x10 0x69 0x10 0x6b 0x10 0x6a>;
			reset-names = "tdm_ahb", "tdm_apb", "tdm_rst";
			dmas = <0x1a 0x14 0x01 0x1a 0x15 0x01>;
			dma-names = "rx", "tx";
			#sound-dai-cells = <0x00>;
			status = "disabled";
			phandle = <0x6c>;
		};

		spdif0@100a0000 {
			compatible = "starfive,sf-spdif";
			reg = <0x00 0x100a0000 0x00 0x1000>;
			clocks = <0x0f 0x9f 0x0f 0xa0 0x0f 0x12>;
			clock-names = "spdif-apb", "spdif-core", "audioclk";
			resets = <0x10 0x5f>;
			reset-names = "rst_apb";
			interrupts = <0x54>;
			interrupt-names = "tx";
			#sound-dai-cells = <0x00>;
			status = "disabled";
			phandle = <0x6d>;
		};

		pwmdac@100b0000 {
			compatible = "starfive,pwmdac";
			reg = <0x00 0x100b0000 0x00 0x1000>;
			clocks = <0x0f 0x0c 0x0f 0x9d 0x0f 0x9e>;
			clock-names = "apb0", "pwmdac-apb", "pwmdac-core";
			resets = <0x10 0x60>;
			reset-names = "rst-apb";
			dmas = <0x1a 0x16 0x01>;
			dma-names = "tx";
			#sound-dai-cells = <0x00>;
			status = "disabled";
			phandle = <0x2d>;
		};

		i2stx@100c0000 {
			compatible = "snps,designware-i2stx";
			reg = <0x00 0x100c0000 0x00 0x1000>;
			clocks = <0x0f 0x0c>;
			clock-names = "i2sclk";
			interrupt-names = "tx";
			#sound-dai-cells = <0x00>;
			dmas = <0x1a 0x1c 0x01>;
			dma-names = "rx";
			status = "disabled";
			phandle = <0x6e>;
		};

		pdm@100d0000 {
			compatible = "starfive,sf-pdm";
			reg = <0x00 0x100d0000 0x00 0x1000>;
			reg-names = "pdm";
			clocks = <0x0f 0xb6 0x0f 0x0c 0x0f 0xb7 0x0f 0x130 0x0f 0x131 0x0f 0x132 0x0f 0x133 0x0f 0xb3>;
			clock-names = "pdm_dmic", "clk_apb0", "pdm_apb", "pdm_dmic0_bclk", "pdm_dmic0_lrck", "pdm_dmic1_bclk", "pdm_dmic1_lrck", "u0_i2srx_3ch_bclk";
			resets = <0x10 0x61 0x10 0x62>;
			reset-names = "pdm_dmic", "pdm_apb";
			#sound-dai-cells = <0x00>;
			status = "disabled";
			phandle = <0x6f>;
		};

		i2srx_3ch@100e0000 {
			compatible = "snps,designware-i2srx";
			reg = <0x00 0x100e0000 0x00 0x1000>;
			clocks = <0x0f 0x0c 0x0f 0xaf 0x0f 0xb0>;
			clock-names = "apb0", "3ch-apb", "3ch-bclk";
			resets = <0x10 0x63 0x10 0x64>;
			reset-names = "rst_apb_rx", "rst_bclk_rx";
			interrupts = <0x2a>;
			interrupt-names = "rx";
			dmas = <0x1a 0x18 0x01>;
			dma-names = "rx";
			#sound-dai-cells = <0x00>;
			status = "disabled";
			phandle = <0x70>;
		};

		i2stx_4ch0@120b0000 {
			compatible = "snps,designware-i2stx-4ch0";
			reg = <0x00 0x120b0000 0x00 0x1000>;
			clocks = <0x0f 0x11 0x0f 0xa2 0x0f 0xa4 0x0f 0x12 0x0f 0xa5 0x0f 0xa7>;
			clock-names = "inner", "bclk-mst", "lrck-mst", "mclk", "bclk0", "lrck0";
			resets = <0x10 0x65 0x10 0x66>;
			reset-names = "rst_apb0", "rst_bclk0";
			interrupts = <0x3a>;
			interrupt-names = "tx";
			dmas = <0x1a 0x2f 0x01>;
			dma-names = "tx";
			#sound-dai-cells = <0x00>;
			status = "disabled";
			phandle = <0x71>;
		};

		i2stx_4ch1@120c0000 {
			compatible = "snps,designware-i2stx-4ch1";
			reg = <0x00 0x120c0000 0x00 0x1000>;
			clocks = <0x0f 0x11 0x0f 0xa9 0x0f 0xab 0x0f 0x12 0x0f 0xac 0x0f 0xae>;
			clock-names = "inner", "bclk-mst1", "lrck-mst1", "mclk", "bclk1", "lrck1";
			resets = <0x10 0x67 0x10 0x68>;
			reset-names = "rst_apb1", "rst_bclk1";
			interrupts = <0x3b>;
			interrupt-names = "tx";
			dmas = <0x1a 0x30 0x01>;
			dma-names = "tx";
			#sound-dai-cells = <0x00>;
			status = "disabled";
			phandle = <0x72>;
		};

		pwm@120d0000 {
			compatible = "starfive,pwm0";
			reg = <0x00 0x120d0000 0x00 0x10000>;
			reg-names = "control";
			clocks = <0x0f 0x79>;
			resets = <0x10 0x6c>;
			starfive,approx-period = <0x1e8480>;
			#pwm-cells = <0x03>;
			starfive,npwm = <0x08>;
			status = "disabled";
			phandle = <0x73>;
		};

		spdif_transmitter {
			compatible = "linux,spdif-dit";
			#sound-dai-cells = <0x00>;
			status = "disabled";
			phandle = <0x74>;
		};

		spdif_receiver {
			compatible = "linux,spdif-dir";
			#sound-dai-cells = <0x00>;
			status = "disabled";
			phandle = <0x75>;
		};

		pwmdac-transmitter {
			compatible = "linux,pwmdac-dit";
			#sound-dai-cells = <0x00>;
			status = "disabled";
			phandle = <0x2e>;
		};

		dmic_codec {
			compatible = "dmic-codec";
			#sound-dai-cells = <0x00>;
			status = "disabled";
			phandle = <0x76>;
		};

		spi@10060000 {
			compatible = "arm,pl022", "arm,primecell";
			reg = <0x00 0x10060000 0x00 0x10000>;
			clocks = <0x0f 0x83>;
			clock-names = "apb_pclk";
			resets = <0x10 0x45>;
			reset-names = "rst_apb";
			interrupts = <0x26>;
			dmas = <0x1a 0x0e 0x01 0x1a 0x0f 0x01>;
			dma-names = "rx", "tx";
			arm,primecell-periphid = <0x41022>;
			num-cs = <0x01>;
			#address-cells = <0x01>;
			#size-cells = <0x00>;
			status = "disabled";
			phandle = <0x77>;
		};

		pcie@2B000000 {
			compatible = "starfive,jh7110-pcie";
			#address-cells = <0x03>;
			#size-cells = <0x02>;
			#interrupt-cells = <0x01>;
			reg = <0x00 0x2b000000 0x00 0x1000000 0x09 0x40000000 0x00 0x10000000>;
			reg-names = "reg", "config";
			device_type = "pci";
			starfive,stg-syscon = <0x11 0xc0 0xc4 0x130 0x1b8>;
			bus-range = <0x00 0xff>;
			ranges = <0x82000000 0x00 0x30000000 0x00 0x30000000 0x00 0x8000000 0xc3000000 0x09 0x00 0x09 0x00 0x00 0x40000000>;
			msi-parent = <0x02>;
			interrupts = <0x38>;
			interrupt-controller;
			interrupt-names = "msi";
			interrupt-parent = <0x02>;
			interrupt-map-mask = <0x00 0x00 0x00 0x07>;
			interrupt-map = <0x00 0x00 0x00 0x01 0x02 0x01 0x00 0x00 0x00 0x02 0x02 0x02 0x00 0x00 0x00 0x03 0x02 0x03 0x00 0x00 0x00 0x04 0x02 0x04>;
			resets = <0x10 0x8b 0x10 0x8c 0x10 0x8d 0x10 0x8e 0x10 0x8f 0x10 0x90>;
			reset-names = "rst_mst0", "rst_slv0", "rst_slv", "rst_brg", "rst_core", "rst_apb";
			clocks = <0x0f 0x60 0x0f 0xc8 0x0f 0xc6 0x0f 0xc7>;
			clock-names = "noc", "tl", "axi_mst0", "apb";
			status = "okay";
			pinctrl-names = "perst-default", "perst-active", "wake-default", "clkreq-default";
			pinctrl-0 = <0x1b>;
			pinctrl-1 = <0x1c>;
			pinctrl-2 = <0x1d>;
			pinctrl-3 = <0x1e>;
			phandle = <0x78>;
		};

		pcie@2C000000 {
			compatible = "starfive,jh7110-pcie";
			#address-cells = <0x03>;
			#size-cells = <0x02>;
			#interrupt-cells = <0x01>;
			reg = <0x00 0x2c000000 0x00 0x1000000 0x09 0xc0000000 0x00 0x10000000>;
			reg-names = "reg", "config";
			device_type = "pci";
			starfive,stg-syscon = <0x11 0x270 0x274 0x2e0 0x368>;
			bus-range = <0x00 0xff>;
			ranges = <0x82000000 0x00 0x38000000 0x00 0x38000000 0x00 0x8000000 0xc3000000 0x09 0x80000000 0x09 0x80000000 0x00 0x40000000>;
			msi-parent = <0x02>;
			interrupts = <0x39>;
			interrupt-controller;
			interrupt-names = "msi";
			interrupt-parent = <0x02>;
			interrupt-map-mask = <0x00 0x00 0x00 0x07>;
			interrupt-map = <0x00 0x00 0x00 0x01 0x02 0x01 0x00 0x00 0x00 0x02 0x02 0x02 0x00 0x00 0x00 0x03 0x02 0x03 0x00 0x00 0x00 0x04 0x02 0x04>;
			resets = <0x10 0x91 0x10 0x92 0x10 0x93 0x10 0x94 0x10 0x95 0x10 0x96>;
			reset-names = "rst_mst0", "rst_slv0", "rst_slv", "rst_brg", "rst_core", "rst_apb";
			clocks = <0x0f 0x60 0x0f 0xcb 0x0f 0xc9 0x0f 0xca>;
			clock-names = "noc", "tl", "axi_mst0", "apb";
			status = "okay";
			pinctrl-names = "perst-default", "perst-active", "wake-default", "clkreq-default";
			pinctrl-0 = <0x1f>;
			pinctrl-1 = <0x20>;
			pinctrl-2 = <0x21>;
			pinctrl-3 = <0x22>;
			phandle = <0x79>;
		};

		mailbox@0 {
			compatible = "starfive,mail_box";
			reg = <0x00 0x13060000 0x00 0x1000>;
			clocks = <0x0f 0x71>;
			clock-names = "clk_apb";
			resets = <0x10 0x44>;
			reset-names = "mbx_rre";
			interrupts = <0x1a 0x1b>;
			#mbox-cells = <0x02>;
			status = "disabled";
			phandle = <0x23>;
		};

		mailbox_client@0 {
			compatible = "starfive,mailbox-test";
			mbox-names = "rx", "tx";
			mboxes = <0x23 0x00 0x01 0x23 0x01 0x00>;
			status = "disabled";
			phandle = <0x7a>;
		};

		dssctrl@295B0000 {
			compatible = "verisilicon,dss-ctrl", "syscon";
			reg = <0x00 0x295b0000 0x00 0x90>;
			phandle = <0x2b>;
		};

		dc8200@29400000 {
			compatible = "starfive,sf-dc8200";
			reg = <0x00 0x29400000 0x00 0x100 0x00 0x29400800 0x00 0x2000>;
			reg-names = "hi", "low";
			status = "okay";
			clocks = <0x0f 0x3c 0x0f 0x3a 0x0f 0x3e 0x0f 0x3d 0x24 0x169 0x24 0x16a 0x24 0x166 0x24 0x167 0x24 0x168 0x24 0x16b 0x0c 0x24 0x163 0x24 0x189 0x24 0x18a>;
			clock-names = "disp_axi", "vout_src", "top_vout_axi", "top_vout_ahb", "dc_pix0", "dc_pix1", "dc_axi", "dc_core", "dc_ahb", "top_vout_lcd", "hdmitx0_pixelclk", "dc8200_pix0", "dc8200_pix0_out", "dc8200_pix1_out";
			resets = <0x10 0x2b 0x10 0xe0 0x10 0xe1 0x10 0xe2 0x10 0x1a>;
			reset-names = "rst_vout_src", "rst_axi", "rst_ahb", "rst_core", "rst_noc_disp";
			phandle = <0x7b>;

			port {
				#address-cells = <0x01>;
				#size-cells = <0x00>;
				phandle = <0x7c>;

				endpoint@0 {
					reg = <0x00>;
					remote-endpoint = <0x25>;
					phandle = <0x28>;
				};

				endpoint@1 {
					reg = <0x01>;
					remote-endpoint = <0x26>;
					phandle = <0x2a>;
				};
			};
		};

		hdmi@29590000 {
			compatible = "starfive,inno-hdmi";
			reg = <0x00 0x29590000 0x00 0x4000>;
			status = "okay";
			clocks = <0x24 0x173 0x24 0x171 0x24 0x172>;
			clock-names = "sysclk", "mclk", "bclk";
			resets = <0x10 0xe9>;
			reset-names = "hdmi_tx";
			pinctrl-names = "default";
			pinctrl-0 = <0x27>;
			phandle = <0x7d>;

			ports {

				port {
					#address-cells = <0x01>;
					#size-cells = <0x00>;
					phandle = <0x7e>;

					endpoint@0 {
						reg = <0x00>;
						remote-endpoint = <0x28>;
						phandle = <0x25>;
					};
				};
			};
		};

		mipi@295d0000 {
			compatible = "starfive,sf_mipi_dsi";
			reg = <0x00 0x295d0000 0x00 0x10000 0x00 0x295e0000 0x00 0x10000 0x00 0x17010000 0x00 0x1000>;
			reg-names = "dsi", "phy", "syscon";
			clocks = <0x24 0x16d 0x24 0x16c 0x24 0x16f 0x24 0x16e 0x24 0x170>;
			clock-names = "sys", "apb", "txesc", "dpi", "dphy_txesc";
			resets = <0x10 0xe3 0x10 0xe4 0x10 0xe5 0x10 0xe6 0x10 0xe7 0x10 0xe8 0x10 0xea 0x10 0xeb>;
			reset-names = "dsi_dpi", "dsi_apb", "dsi_rxesc", "dsi_sys", "dsi_txbytehs", "dsi_txesc", "dphy_sys", "dphy_txbytehs";
			status = "okay";
			rockchip,panel = <0x29>;
			data-lanes-num = <0x01>;
			phandle = <0x7f>;

			ports {

				port {
					#address-cells = <0x01>;
					#size-cells = <0x00>;
					phandle = <0x80>;

					endpoint@0 {
						reg = <0x00>;
						remote-endpoint = <0x2a>;
						phandle = <0x26>;
					};
				};
			};

			display-timings {

				timing0 {
					bits-per-pixel = <0x18>;
					clock-frequency = <0x9896800>;
					hfront-porch = <0x78>;
					hsync-len = <0x14>;
					hback-porch = <0x15>;
					hactive = <0x4b0>;
					vfront-porch = <0x15>;
					vsync-len = <0x03>;
					vback-porch = <0x12>;
					vactive = <0x780>;
					hsync-active = <0x00>;
					vsync-active = <0x00>;
					de-active = <0x01>;
					pixelclk-active = <0x00>;
				};
			};
		};

		dsi-host {
			compatible = "starfive,mipi-dsi";
			status = "okay";
			phandle = <0x81>;
		};

		hdmi-output {
			compatible = "verisilicon,hdmi-encoder";
			verisilicon,dss-syscon = <0x2b>;
			verisilicon,mux-mask = <0x70 0x380>;
			verisilicon,mux-val = <0x40 0x280>;
			status = "disabled";
			phandle = <0x82>;
		};

		mipi-dphy@295e0000 {
			compatible = "starfive,jh7100-mipi-dphy-tx";
			reg = <0x00 0x295e0000 0x00 0x10000>;
			clocks = <0x24 0x170>;
			clock-names = "dphy_txesc";
			resets = <0x10 0xea 0x10 0xeb>;
			reset-names = "dphy_sys", "dphy_txbytehs";
			#phy-cells = <0x00>;
			status = "disabled";
			phandle = <0x83>;
		};

		snd-card {
			compatible = "simple-audio-card";
			simple-audio-card,name = "Starfive-Multi-Sound-Card";
			#address-cells = <0x01>;
			#size-cells = <0x00>;
			phandle = <0x84>;

			simple-audio-card,dai-link@0 {
				reg = <0x00>;
				format = "left_j";
				bitclock-master = <0x2c>;
				frame-master = <0x2c>;
				status = "okay";

				cpu {
					sound-dai = <0x2d>;
					phandle = <0x2c>;
				};

				codec {
					sound-dai = <0x2e>;
				};
			};
		};

		e24@0 {
			compatible = "starfive,e24";
			reg = <0x00 0xc0110000 0x00 0x1000 0x00 0xc0111000 0x00 0x1f000>;
			reg-names = "ecmd", "espace";
			clocks = <0x0f 0xd6 0x0f 0xd7 0x0f 0xd8>;
			clock-names = "clk_rtc", "clk_core", "clk_dbg";
			resets = <0x10 0x84>;
			reset-names = "e24_core";
			starfive,stg-syscon = <0x11>;
			interrupt-parent = <0x02>;
			firmware-name = "e24_elf";
			irq-mode = <0x01>;
			mbox-names = "tx", "rx";
			mboxes = <0x23 0x00 0x02 0x23 0x02 0x00>;
			#address-cells = <0x01>;
			#size-cells = <0x01>;
			ranges = <0xc0000000 0x00 0xc0000000 0x200000>;
			status = "disabled";
			phandle = <0x85>;

			dsp@0 {
			};
		};

		dmc@100b0000 {
			compatible = "starfive,jh7110-dmc";
			reg = <0x00 0x15700000 0x00 0x10000 0x00 0x13000000 0x00 0x10000>;
			resets = <0x10 0x26 0x10 0x27 0x10 0x28>;
			reset-names = "axi", "osc", "apb";
			clock-frequency = <0x855>;
			u-boot,dm-spl;
			phandle = <0x86>;
		};
	};

	aliases {
		spi0 = "/soc/spi@13010000";
		gpio0 = "/soc/gpio@13040000";
		ethernet0 = "/soc/ethernet@16030000";
		ethernet1 = "/soc/ethernet@16040000";
		mmc0 = "/soc/sdio0@16010000";
		mmc1 = "/soc/sdio1@16020000";
		i2c0 = "/soc/i2c5@12050000";
	};

	chosen {
		boot-hartid = <0x01>;
		bootargs = "console=tty1 console=ttyS0,115200  debug rootwait  earlycon=sbi";
		stdout-path = "/soc/serial@10000000:115200";
		starfive,boot-hart-id = <0x01>;
		u-boot,dm-spl;
	};

	memory@80000000 {
		device_type = "memory";
		reg = <0x00 0x40000000 0x01 0x00>;
		u-boot,dm-spl;
	};

	reserved-memory {
		#size-cells = <0x02>;
		#address-cells = <0x02>;
		ranges;

		opensbi {
			reg = <0x00 0x40000000 0x00 0x80000>;
			no-map;
		};
	};

	gpio-restart {
		compatible = "gpio-restart";
		gpios = <0x2f 0x23 0x00>;
	};

	firmware {
		spi0 = "/soc/qspi@11860000";
		u-boot,dm-spl;
	};

	config {
		u-boot,dm-spl;
		u-boot,spl-payload-offset = <0x100000>;
	};

	__symbols__ {
		osc = "/osc";
		gmac1_rmii_refin = "/gmac1_rmii_refin";
		gmac1_rgmii_rxin = "/gmac1_rgmii_rxin";
		i2stx_bclk_ext = "/i2stx_bclk_ext";
		i2stx_lrck_ext = "/i2stx_lrck_ext";
		i2srx_bclk_ext = "/i2srx_bclk_ext";
		i2srx_lrck_ext = "/i2srx_lrck_ext";
		tdm_ext = "/tdm_ext";
		mclk_ext = "/mclk_ext";
		jtag_tck_inner = "/jtag_tck_inner";
		bist_apb = "/bist_apb";
		stg_apb = "/stg_apb";
		gmac0_rmii_refin = "/gmac0_rmii_refin";
		gmac0_rgmii_rxin = "/gmac0_rgmii_rxin";
		clk_rtc = "/clk_rtc";
		hdmitx0_pixelclk = "/hdmitx0_pixelclk";
		mipitx_dphy_rxesc = "/mipitx_dphy_rxesc";
		mipitx_dphy_txbytehs = "/mipitx_dphy_txbytehs";
		cpus = "/cpus";
		cpu0 = "/cpus/cpu@0";
		cpu0intctrl = "/cpus/cpu@0/interrupt-controller";
		cpu1 = "/cpus/cpu@1";
		cpu1intctrl = "/cpus/cpu@1/interrupt-controller";
		cpu2 = "/cpus/cpu@2";
		cpu2intctrl = "/cpus/cpu@2/interrupt-controller";
		cpu3 = "/cpus/cpu@3";
		cpu3intctrl = "/cpus/cpu@3/interrupt-controller";
		cpu4 = "/cpus/cpu@4";
		cpu4intctrl = "/cpus/cpu@4/interrupt-controller";
		soc = "/soc";
		cachectrl = "/soc/cache-controller@2010000";
		aon_syscon = "/soc/aon_syscon@17010000";
		stg_syscon = "/soc/stg_syscon@10240000";
		sys_syscon = "/soc/sys_syscon@13030000";
		clint = "/soc/clint@2000000";
		plic = "/soc/plic@c000000";
		clkgen = "/soc/clock-controller";
		clkvout = "/soc/clock-controller@295C0000";
		clkisp = "/soc/clock-controller@19810000";
		qspi = "/soc/spi@13010000";
		nor_flash = "/soc/spi@13010000/nor-flash@0";
		otp = "/soc/otp@17050000";
		usbdrd30 = "/soc/usbdrd";
		usbdrd_cdns3 = "/soc/usbdrd/usb@10100000";
		timer = "/soc/timer@13050000";
		wdog = "/soc/wdog@13070000";
		rtc = "/soc/rtc@17040000";
		pmu = "/soc/pmu@17030000";
		uart0 = "/soc/serial@10000000";
		uart1 = "/soc/serial@10010000";
		uart2 = "/soc/serial@10020000";
		uart3 = "/soc/serial@12000000";
		uart4 = "/soc/serial@12010000";
		uart5 = "/soc/serial@12020000";
		dma = "/soc/dma-controller@16050000";
		gpio = "/soc/gpio@13040000";
		uart0_pins = "/soc/gpio@13040000/uart0-0";
		mmc0_pins = "/soc/gpio@13040000/mmc0-pins";
		sdcard1_pins = "/soc/gpio@13040000/sdcard1-pins";
		pcie0_perst_default = "/soc/gpio@13040000/pcie0_perst_default";
		pcie0_perst_active = "/soc/gpio@13040000/pcie0_perst_active";
		pcie0_wake_default = "/soc/gpio@13040000/pcie0_wake_default";
		pcie0_clkreq_default = "/soc/gpio@13040000/pcie0_clkreq_default";
		pcie1_perst_default = "/soc/gpio@13040000/pcie1_perst_default";
		pcie1_perst_active = "/soc/gpio@13040000/pcie1_perst_active";
		pcie1_wake_default = "/soc/gpio@13040000/pcie1_wake_default";
		pcie1_clkreq_default = "/soc/gpio@13040000/pcie1_clkreq_default";
		i2c2_pins = "/soc/gpio@13040000/i2c2-0";
		i2c5_pins = "/soc/gpio@13040000/i2c5-0";
		hdmi_pins = "/soc/gpio@13040000/hdmi-0";
		gpioa = "/soc/gpio@17020000";
		trng = "/soc/trng@1600C000";
		sec_dma = "/soc/sec_dma@16008000";
		crypto = "/soc/crypto@16000000";
		i2c0 = "/soc/i2c@10030000";
		i2c1 = "/soc/i2c@10040000";
		i2c2 = "/soc/i2c@10050000";
		rm68200_panel = "/soc/i2c@10050000/rm68200_panel@45";
		i2c3 = "/soc/i2c@12030000";
		i2c4 = "/soc/i2c@12040000";
		i2c5 = "/soc/i2c5@12050000";
		pmic = "/soc/i2c5@12050000/axp15060_reg@36";
		i2c6 = "/soc/i2c@12060000";
		sdio0 = "/soc/sdio0@16010000";
		sdio1 = "/soc/sdio1@16020000";
		vin_sysctl = "/soc/vin_sysctl@19800000";
		jpu = "/soc/jpu@11900000";
		vpu_dec = "/soc/vpu_dec@130A0000";
		vpu_enc = "/soc/vpu_enc@130B0000";
		rstgen = "/soc/reset-controller";
		stmmac_axi_setup = "/soc/stmmac-axi-config";
		gmac0 = "/soc/ethernet@16030000";
		phy0 = "/soc/ethernet@16030000/ethernet-phy@0";
		gmac1 = "/soc/ethernet@16040000";
		phy1 = "/soc/ethernet@16040000/ethernet-phy@1";
		gpu = "/soc/gpu@18000000";
		can0 = "/soc/can@130d0000";
		can1 = "/soc/can@130e0000";
		tdm = "/soc/tdm@10090000";
		spdif0 = "/soc/spdif0@100a0000";
		pwmdac = "/soc/pwmdac@100b0000";
		i2stx = "/soc/i2stx@100c0000";
		pdm = "/soc/pdm@100d0000";
		i2srx_3ch = "/soc/i2srx_3ch@100e0000";
		i2stx_4ch0 = "/soc/i2stx_4ch0@120b0000";
		i2stx_4ch1 = "/soc/i2stx_4ch1@120c0000";
		ptc = "/soc/pwm@120d0000";
		spdif_transmitter = "/soc/spdif_transmitter";
		spdif_receiver = "/soc/spdif_receiver";
		pwmdac_codec = "/soc/pwmdac-transmitter";
		dmic_codec = "/soc/dmic_codec";
		spi0 = "/soc/spi@10060000";
		pcie0 = "/soc/pcie@2B000000";
		pcie1 = "/soc/pcie@2C000000";
		mailbox_contrl0 = "/soc/mailbox@0";
		mailbox_client0 = "/soc/mailbox_client@0";
		dssctrl = "/soc/dssctrl@295B0000";
		dc8200 = "/soc/dc8200@29400000";
		vopb_out = "/soc/dc8200@29400000/port";
		vopb_out_hdmi = "/soc/dc8200@29400000/port/endpoint@0";
		vopb_out_mipi = "/soc/dc8200@29400000/port/endpoint@1";
		hdmi = "/soc/hdmi@29590000";
		hdmi_in = "/soc/hdmi@29590000/ports/port";
		hdmi_in_vopb = "/soc/hdmi@29590000/ports/port/endpoint@0";
		mipi_dsi0 = "/soc/mipi@295d0000";
		mipi_in = "/soc/mipi@295d0000/ports/port";
		mipi_in_vopb = "/soc/mipi@295d0000/ports/port/endpoint@0";
		dsi_host = "/soc/dsi-host";
		hdmi_output = "/soc/hdmi-output";
		mipi_dphy = "/soc/mipi-dphy@295e0000";
		sound = "/soc/snd-card";
		sndcpu0 = "/soc/snd-card/simple-audio-card,dai-link@0/cpu";
		co_process = "/soc/e24@0";
		dmc = "/soc/dmc@100b0000";
	};
};
